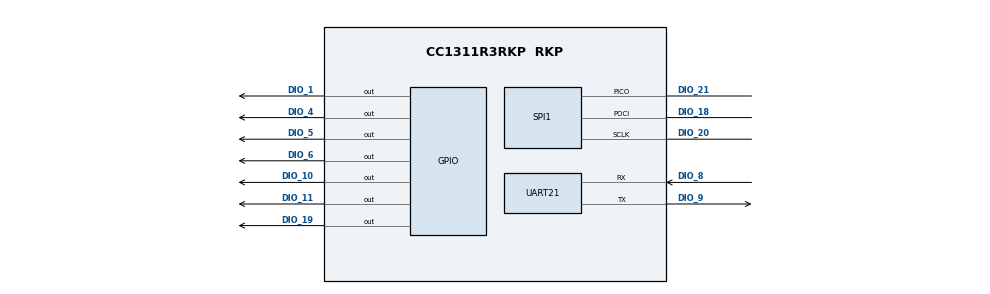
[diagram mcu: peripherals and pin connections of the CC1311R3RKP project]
/**
 * @cliArgs --device "CC1311R3RKP" --part "Default" --package "RKP" --rtos "nortos" --product "simplelink_cc13xx_cc26xx_sdk@8.30.01.01"
 * @versions {"tool":"1.21.1+3772"}
 */

/**
 * Import the modules used in this configuration.
 */
const custom   = scripting.addModule("/ti/devices/radioconfig/custom");
const rfdesign = scripting.addModule("/ti/devices/radioconfig/rfdesign");
const Board    = scripting.addModule("/ti/drivers/Board");
const GPIO     = scripting.addModule("/ti/drivers/GPIO", {}, false);
const GPIO1    = GPIO.addInstance();
const GPIO2    = GPIO.addInstance();
const GPIO3    = GPIO.addInstance();
const GPIO4    = GPIO.addInstance();
const GPIO5    = GPIO.addInstance();
const GPIO6    = GPIO.addInstance();
const GPIO7    = GPIO.addInstance();
const GPIO8    = GPIO.addInstance();
const RF       = scripting.addModule("/ti/drivers/RF");
const SPI      = scripting.addModule("/ti/drivers/SPI", {}, false);
const SPI1     = SPI.addInstance();
const UART2    = scripting.addModule("/ti/drivers/UART2", {}, false);
const UART21   = UART2.addInstance();

/**
 * Write custom configuration values to the imported modules.
 */
custom.prop8                                       = ["custom868"];
custom.radioConfigcustom868.$name                  = "ti_devices_radioconfig_settings_prop0";
custom.radioConfigcustom868.symbolRate             = 250.000;
custom.radioConfigcustom868.txPower                = "10";
custom.radioConfigcustom868.whitening              = "CC1101/CC2500 compatible";
custom.radioConfigcustom868.syncWord               = 0xD391D391;
custom.radioConfigcustom868.deviation              = 165.0;
custom.radioConfigcustom868.rxFilterBw             = "621.6";
custom.radioConfigcustom868.carrierFrequency       = 863.9900;
custom.radioConfigcustom868.codeExportConfig.$name = "ti_devices_radioconfig_code_export_param0";

Board.generateInitializationFunctions = false;

GPIO1.$name              = "CONFIG_GPIO_EPD_CS";
GPIO1.mode               = "Output";
GPIO1.initialOutputState = "High";
GPIO1.gpioPin.$assign    = "DIO_1";

GPIO2.$name           = "CONFIG_GPIO_EPD_PWR";
GPIO2.mode            = "Output";
GPIO2.gpioPin.$assign = "DIO_4";

GPIO3.$name           = "CONFIG_GPIO_EPD_SDI";
GPIO3.mode            = "Output";
GPIO3.gpioPin.$assign = "DIO_5";

GPIO4.$name           = "CONFIG_GPIO_EPD_CLK";
GPIO4.mode            = "Output";
GPIO4.gpioPin.$assign = "DIO_6";

GPIO5.$name              = "CONFIG_GPIO_EPD_RST";
GPIO5.mode               = "Output";
GPIO5.initialOutputState = "High";
GPIO5.gpioPin.$assign    = "DIO_10";

GPIO6.$name           = "CONFIG_GPIO_EPD_BUSY";
GPIO6.pull            = "Pull Up";
GPIO6.gpioPin.$assign = "DIO_11";

GPIO7.$name = "CONFIG_GPIO_0";

GPIO8.$name              = "CONFIG_GPIO_FLASH_CS";
GPIO8.mode               = "Output";
GPIO8.initialOutputState = "High";
GPIO8.gpioPin.$assign    = "DIO_19";

const CCFG              = scripting.addModule("/ti/devices/CCFG", {}, false);
CCFG.ccfgTemplate.$name = "ti_devices_CCFG_CCFGCC26XXTemplate0";

SPI1.$name               = "CONFIG_SPI_FLASH";
SPI1.spi.sclkPin.$assign = "DIO_20";
SPI1.spi.pociPin.$assign = "DIO_18";
SPI1.spi.picoPin.$assign = "DIO_21";

UART21.$name              = "DEBUG_UART";
UART21.uart.txPin.$assign = "DIO_9";
UART21.uart.rxPin.$assign = "DIO_8";

/**
 * Pinmux solution for unlocked pins/peripherals. This ensures that minor changes to the automatic solver in a future
 * version of the tool will not impact the pinmux you originally saw.  These lines can be completely deleted in order to
 * re-solve from scratch.
 */
GPIO7.gpioPin.$suggestSolution         = "DIO_0";
SPI1.spi.$suggestSolution              = "SSI0";
SPI1.spi.dmaRxChannel.$suggestSolution = "DMA_CH3";
SPI1.spi.dmaTxChannel.$suggestSolution = "DMA_CH4";
UART21.uart.$suggestSolution           = "UART0";
